# STM32U073xx register map
File version: 1.0
Registers are 32-bit, read-write, reset 0x0 unless marked. A register's access mark holds for its fields unless they carry their own. Offsets are from the block's base; [hi:lo] are bit positions; 'fields as' and 'values as' point back to an identical list.

## VREFBUF
Base 0x40010030
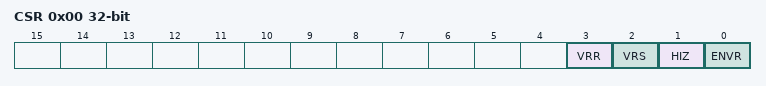
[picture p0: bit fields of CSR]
0x00 CSR — VREFBUF control and status register
  [3] VRR — Voltage reference buffer ready
  [2] VRS — Voltage reference scale
    0=SCALE0 (Voltage reference scale 0 (VREF_OUT1)); 1=SCALE1 (Voltage reference scale 1 (VREF_OUT2))
  [1] HIZ — High impedance mode
  [0] ENVR — Voltage reference buffer enable
0x04 CCR — VREFBUF calibration and control register
  [5:0] TRIM — TRIM[5:0] bits (Trimming code)

## COMP1 — Comparator
Base 0x40010200
Same registers: COMP2 0x40010204
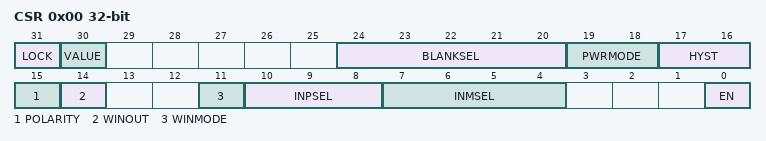
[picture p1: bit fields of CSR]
0x00 CSR — COMP control and status register
  [31] LOCK — COMPx Lock Bit
  [30] VALUE — Comparator output level
  [24:20] BLANKSEL — COMPx blanking source selection bits
    0=NONE (Comparator output without blanking); 1=TIM1_OC4 (Comparator output blanking source TIM1 OC4 (common to all COMP instances: COMP1, COMP2)); 2=TIM1_OC5 (Comparator output blanking source TIM1 OC5 (common to all COMP instances: COMP1, COMP2)); 4=TIM2_OC3 (Comparator output blanking source TIM2 OC3 (common to all COMP instances: COMP1, COMP2)); 8=TIM3_OC3 (Comparator output blanking source TIM3 OC3 (common to all COMP instances: COMP1, COMP2)); 16=TIM15_OC2 (Comparator output blanking source TIM15 OC2 (common to all COMP instances: COMP1, COMP2))
  [19:18] PWRMODE — COMPx Power Mode of the comparator
    0=HIGHSPEED (COMP power mode to high speed); 1=MEDIUMSPEED (COMP power mode to medium speed); 3=ULTRALOWPOWER (COMP power mode to ultra-low power)
  [17:16] HYST — COMPx hysteresis selection bits
    0=NONE (No hysteresis); 1=LOW (Hysteresis level low); 2=MEDIUM (Hysteresis level medium); 3=HIGH (Hysteresis level high)
  [15] POLARITY — COMPx polarity selection bit
    0=NONINVERTED (COMP output polarity is not inverted: comparator output is high when the plus (non-inverting) input is at a higher voltage than the minus (inverting) input); 1=INVERTED (COMP output polarity is inverted: comparator output is low when the plus (non-inverting) input is at a lower voltage than the minus (inverting) input)
  [14] WINOUT — COMPx polarity selection bit
  [11] WINMODE — COMPx Windows mode selection bit
  [10:8] INPSEL — COMPx input plus selection bit
    0=IO1 (Comparator input plus connected to IO1 (pin PC5 for COMP1, pin PB4 for COMP2)); 1=IO2 (Comparator input plus connected to IO2 (pin PB2 for COMP1, pin PB6 for COMP2)); 2=IO3 (Comparator input plus connected to IO3 (pin PA1 for COMP1, pin PA3 for COMP2)); 3=IO4 (Comparator input plus connected to IO4 (pin PA9 for COMP1, pin PD10 for COMP2)); 4=IO5 (Comparator input plus connected to IO5 (pin PC6 for COMP1))
  [7:4] INMSEL — COMPx input minus selection bit
    0=MINUS_1_4VREFINT (Comparator input minus connected to 1/4 VrefInt); 1=MINUS_1_2VREFINT (Comparator input minus connected to 1/2 VrefInt); 2=MINUS_3_4VREFINT (Comparator input minus connected to 3/4 VrefInt); 3=VREFINT (Comparator input minus connected to VrefInt); 4=DAC1_CH1 (Comparator input minus connected to DAC1 channel 1 (DAC_OUT1)); 5=IO1 (Comparator input minus connected to IO1 (pin PC4 for COMP1, pin PB7 for COMP2)); 6=IO2 (Comparator input minus connected to IO2 (pin PB1 for COMP1, pin PB3 for COMP2)); 7=IO3 (Comparator input minus connected to IO3 (pin PA0 for COMP1, pin PA2 for COMP2)); 8=IO4 (Comparator input minus connected to IO4 (pin PA4 for COMP1, pin PA4 for COMP2)); 9=IO5 (Comparator input minus connected to IO5 (pin PA5 for COMP1, pin PA5 for COMP2))
  [0] EN — COMPx enable bit

## COMP12_COMMON
Base 0x40010200; alternate view of COMP1
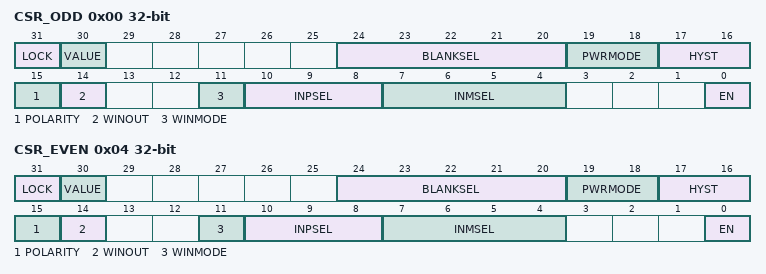
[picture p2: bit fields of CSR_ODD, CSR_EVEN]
0x00 CSR_ODD — COMP control and status register located in register of comparator instance odd, used for bits common to several COMP instances
  [31] LOCK — COMPx Lock Bit
  [30] VALUE — Comparator output level
  [24:20] BLANKSEL — COMPx blanking source selection bits
    0=NONE (Comparator output without blanking); 1=TIM1_OC4 (Comparator output blanking source TIM1 OC4 (common to all COMP instances: COMP1, COMP2)); 2=TIM1_OC5 (Comparator output blanking source TIM1 OC5 (common to all COMP instances: COMP1, COMP2)); 4=TIM2_OC3 (Comparator output blanking source TIM2 OC3 (common to all COMP instances: COMP1, COMP2)); 8=TIM3_OC3 (Comparator output blanking source TIM3 OC3 (common to all COMP instances: COMP1, COMP2)); 16=TIM15_OC2 (Comparator output blanking source TIM15 OC2 (common to all COMP instances: COMP1, COMP2))
  [19:18] PWRMODE — COMPx Power Mode of the comparator
    0=HIGHSPEED (COMP power mode to high speed); 1=MEDIUMSPEED (COMP power mode to medium speed); 3=ULTRALOWPOWER (COMP power mode to ultra-low power)
  [17:16] HYST — COMPx hysteresis selection bits
    0=NONE (No hysteresis); 1=LOW (Hysteresis level low); 2=MEDIUM (Hysteresis level medium); 3=HIGH (Hysteresis level high)
  [15] POLARITY — COMPx polarity selection bit
    0=NONINVERTED (COMP output polarity is not inverted: comparator output is high when the plus (non-inverting) input is at a higher voltage than the minus (inverting) input); 1=INVERTED (COMP output polarity is inverted: comparator output is low when the plus (non-inverting) input is at a lower voltage than the minus (inverting) input)
  [14] WINOUT — COMPx polarity selection bit
  [11] WINMODE — COMPx Windows mode selection bit
  [10:8] INPSEL — COMPx input plus selection bit
    0=IO1 (Comparator input plus connected to IO1 (pin PC5 for COMP1, pin PB4 for COMP2)); 1=IO2 (Comparator input plus connected to IO2 (pin PB2 for COMP1, pin PB6 for COMP2)); 2=IO3 (Comparator input plus connected to IO3 (pin PA1 for COMP1, pin PA3 for COMP2)); 3=IO4 (Comparator input plus connected to IO4 (pin PA9 for COMP1, pin PD10 for COMP2)); 4=IO5 (Comparator input plus connected to IO5 (pin PC6 for COMP1))
  [7:4] INMSEL — COMPx input minus selection bit
    0=MINUS_1_4VREFINT (Comparator input minus connected to 1/4 VrefInt); 1=MINUS_1_2VREFINT (Comparator input minus connected to 1/2 VrefInt); 2=MINUS_3_4VREFINT (Comparator input minus connected to 3/4 VrefInt); 3=VREFINT (Comparator input minus connected to VrefInt); 4=DAC1_CH1 (Comparator input minus connected to DAC1 channel 1 (DAC_OUT1)); 5=IO1 (Comparator input minus connected to IO1 (pin PC4 for COMP1, pin PB7 for COMP2)); 6=IO2 (Comparator input minus connected to IO2 (pin PB1 for COMP1, pin PB3 for COMP2)); 7=IO3 (Comparator input minus connected to IO3 (pin PA0 for COMP1, pin PA2 for COMP2)); 8=IO4 (Comparator input minus connected to IO4 (pin PA4 for COMP1, pin PA4 for COMP2)); 9=IO5 (Comparator input minus connected to IO5 (pin PA5 for COMP1, pin PA5 for COMP2))
  [0] EN — COMPx enable bit
0x04 CSR_EVEN — COMP control and status register located in register of comparator instance even, used for bits common to several COMP instances
  fields as CSR_ODD
